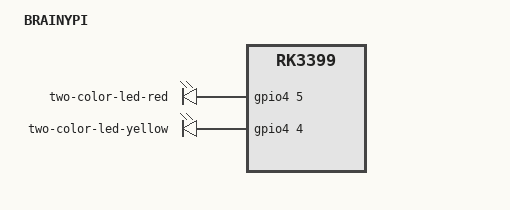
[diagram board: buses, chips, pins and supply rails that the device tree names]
// Definitions for two-color-led module
/dts-v1/;
/plugin/;

/ {
	model = "BRAINYPI";
	compatible = "rockchip,brainypi","rockchip,rk3399";

	fragment@0 {
		target-path = "/";

		__overlay__ {

			two-color-led {
				compatible = "gpio-leds";
				status = "okay";
				two-color-led-red {
					gpios = <&gpio4 5 0>; //0: GPIO_ACTIVE_HIGH
					default-state = "off";
				};

				two-color-led-yellow {
					gpios = <&gpio4 4 0>; //0: GPIO_ACTIVE_HIGH
					default-state = "on";
				};
			};
		};
	};
};
